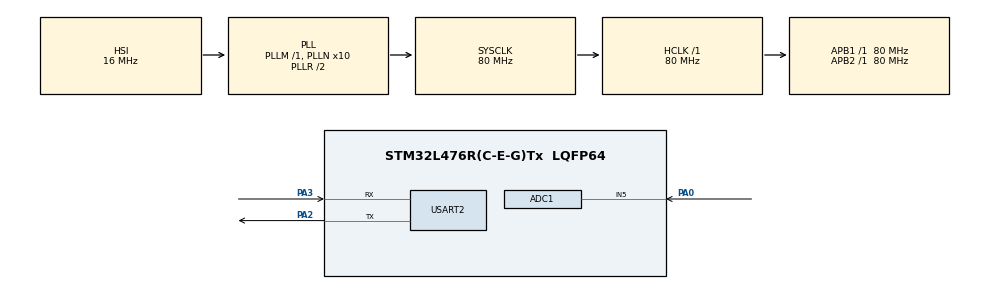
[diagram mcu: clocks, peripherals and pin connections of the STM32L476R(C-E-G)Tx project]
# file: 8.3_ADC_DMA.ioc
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ADC1.Channel-0\#ChannelRegularConversion=ADC_CHANNEL_5
ADC1.ClockPrescaler=ADC_CLOCK_ASYNC_DIV1
ADC1.ContinuousConvMode=ENABLE
ADC1.DMAContinuousRequests=ENABLE
ADC1.NbrOfConversionFlag=1
ADC1.OffsetNumber-0\#ChannelRegularConversion=ADC_OFFSET_NONE
ADC1.Rank-0\#ChannelRegularConversion=1
ADC1.SamplingTime-0\#ChannelRegularConversion=ADC_SAMPLETIME_2CYCLES_5
ADC1.master=1
Dma.ADC1.0.Direction=DMA_PERIPH_TO_MEMORY
Dma.ADC1.0.Instance=DMA1_Channel1
Dma.ADC1.0.MemDataAlignment=DMA_MDATAALIGN_HALFWORD
Dma.ADC1.0.MemInc=DMA_MINC_ENABLE
Dma.ADC1.0.Mode=DMA_CIRCULAR
Dma.ADC1.0.PeriphDataAlignment=DMA_PDATAALIGN_HALFWORD
Dma.ADC1.0.PeriphInc=DMA_PINC_DISABLE
Dma.ADC1.0.Priority=DMA_PRIORITY_LOW
Dma.Request0=ADC1
Mcu.Family=STM32L4
Mcu.Name=STM32L476R(C-E-G)Tx
Mcu.Package=LQFP64
NVIC.DMA1_Channel1_IRQn=true\:0\:0\:false\:false\:true\:false\:true\:true
NVIC.PriorityGroup=NVIC_PRIORITYGROUP_4
PA0.Signal=ADCx_IN5
PA13\ (JTMS-SWDIO).Mode=Serial_Wire
PA13\ (JTMS-SWDIO).Signal=SYS_JTMS-SWDIO
PA14\ (JTCK-SWCLK).Mode=Serial_Wire
PA14\ (JTCK-SWCLK).Signal=SYS_JTCK-SWCLK
PA2.Mode=Asynchronous
PA2.Signal=USART2_TX
PA3.Mode=Asynchronous
PA3.Signal=USART2_RX
ProjectManager.HeapSize=0x200
ProjectManager.StackSize=0x400
ProjectManager.TargetToolchain=STM32CubeIDE
RCC.ADCFreq_Value=64000000
RCC.AHBFreq_Value=80000000
RCC.APB1Freq_Value=80000000
RCC.APB1TimFreq_Value=80000000
RCC.APB2Freq_Value=80000000
RCC.APB2TimFreq_Value=80000000
RCC.CortexFreq_Value=80000000
RCC.HCLKFreq_Value=80000000
RCC.HSE_VALUE=8000000
RCC.HSI_VALUE=16000000
RCC.LSE_VALUE=32768
RCC.MSI_VALUE=4000000
RCC.PLLN=10
RCC.PLLSourceVirtual=RCC_PLLSOURCE_HSI
RCC.SYSCLKFreq_VALUE=80000000
RCC.SYSCLKSource=RCC_SYSCLKSOURCE_PLLCLK
RCC.USBFreq_Value=64000000
RCC.VCOOutputFreq_Value=160000000
SH.ADCx_IN5.0=ADC1_IN5,IN5-Single-Ended
USART2.VirtualMode-Asynchronous=VM_ASYNC
board=custom

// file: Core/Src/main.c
/* USER CODE BEGIN Header */
/**
  ******************************************************************************
  * @file           : main.c
  * @brief          : Main program body
  ******************************************************************************
  * @attention
  *
  * Copyright (c) 2024 STMicroelectronics.
  * All rights reserved.
  *
  * This software is licensed under terms that can be found in the LICENSE file
  * in the root directory of this software component.
  * If no LICENSE file comes with this software, it is provided AS-IS.
  *
  ******************************************************************************
  */
/* USER CODE END Header */
#include "main.h"

/* USER CODE BEGIN Includes */
#include <stdio.h>
/* USER CODE END Includes */

ADC_HandleTypeDef hadc1;
DMA_HandleTypeDef hdma_adc1;

UART_HandleTypeDef huart2;

/* USER CODE BEGIN PV */
//uint32_t  port_value;
//uint32_t ra;
uint16_t adc_buf[4096];
/* USER CODE END PV */

void SystemClock_Config(void);
static void MX_GPIO_Init(void);
static void MX_DMA_Init(void);
static void MX_ADC1_Init(void);
static void MX_USART2_UART_Init(void);

int main(void)
{

  /* MCU Configuration--------------------------------------------------------*/

  /* Reset of all peripherals, Initializes the Flash interface and the Systick. */
  HAL_Init();

  /* Configure the system clock */
  SystemClock_Config();

  /* Initialize all configured peripherals */
  MX_GPIO_Init();
  MX_DMA_Init();
  MX_ADC1_Init();
  MX_USART2_UART_Init();
  /* USER CODE BEGIN 2 */
  HAL_ADC_Start_DMA(&hadc1, (uint32_t *)adc_buf, sizeof(adc_buf));
  /* USER CODE END 2 */

  /* Infinite loop */
  while (1)
  {

  }
}

void SystemClock_Config(void)
{
  RCC_OscInitTypeDef RCC_OscInitStruct = {0};
  RCC_ClkInitTypeDef RCC_ClkInitStruct = {0};

  /** Configure the main internal regulator output voltage
  */
  if (HAL_PWREx_ControlVoltageScaling(PWR_REGULATOR_VOLTAGE_SCALE1) != HAL_OK)
  {
    Error_Handler();
  }

  /** Initializes the RCC Oscillators according to the specified parameters
  * in the RCC_OscInitTypeDef structure.
  */
  RCC_OscInitStruct.OscillatorType = RCC_OSCILLATORTYPE_HSI;
  RCC_OscInitStruct.HSIState = RCC_HSI_ON;
  RCC_OscInitStruct.HSICalibrationValue = RCC_HSICALIBRATION_DEFAULT;
  RCC_OscInitStruct.PLL.PLLState = RCC_PLL_ON;
  RCC_OscInitStruct.PLL.PLLSource = RCC_PLLSOURCE_HSI;
  RCC_OscInitStruct.PLL.PLLM = 1;
  RCC_OscInitStruct.PLL.PLLN = 10;
  RCC_OscInitStruct.PLL.PLLP = RCC_PLLP_DIV7;
  RCC_OscInitStruct.PLL.PLLQ = RCC_PLLQ_DIV2;
  RCC_OscInitStruct.PLL.PLLR = RCC_PLLR_DIV2;
  if (HAL_RCC_OscConfig(&RCC_OscInitStruct) != HAL_OK)
  {
    Error_Handler();
  }

  /** Initializes the CPU, AHB and APB buses clocks
  */
  RCC_ClkInitStruct.ClockType = RCC_CLOCKTYPE_HCLK|RCC_CLOCKTYPE_SYSCLK
                              |RCC_CLOCKTYPE_PCLK1|RCC_CLOCKTYPE_PCLK2;
  RCC_ClkInitStruct.SYSCLKSource = RCC_SYSCLKSOURCE_PLLCLK;
  RCC_ClkInitStruct.AHBCLKDivider = RCC_SYSCLK_DIV1;
  RCC_ClkInitStruct.APB1CLKDivider = RCC_HCLK_DIV1;
  RCC_ClkInitStruct.APB2CLKDivider = RCC_HCLK_DIV1;

  if (HAL_RCC_ClockConfig(&RCC_ClkInitStruct, FLASH_LATENCY_4) != HAL_OK)
  {
    Error_Handler();
  }
}

static void MX_ADC1_Init(void)
{

  ADC_MultiModeTypeDef multimode = {0};
  ADC_ChannelConfTypeDef sConfig = {0};

  /** Common config
  */
  hadc1.Instance = ADC1;
  hadc1.Init.ClockPrescaler = ADC_CLOCK_ASYNC_DIV1;
  hadc1.Init.Resolution = ADC_RESOLUTION_12B;
  hadc1.Init.DataAlign = ADC_DATAALIGN_RIGHT;
  hadc1.Init.ScanConvMode = ADC_SCAN_DISABLE;
  hadc1.Init.EOCSelection = ADC_EOC_SINGLE_CONV;
  hadc1.Init.LowPowerAutoWait = DISABLE;
  hadc1.Init.ContinuousConvMode = ENABLE;
  hadc1.Init.NbrOfConversion = 1;
  hadc1.Init.DiscontinuousConvMode = DISABLE;
  hadc1.Init.ExternalTrigConv = ADC_SOFTWARE_START;
  hadc1.Init.ExternalTrigConvEdge = ADC_EXTERNALTRIGCONVEDGE_NONE;
  hadc1.Init.DMAContinuousRequests = ENABLE;
  hadc1.Init.Overrun = ADC_OVR_DATA_PRESERVED;
  hadc1.Init.OversamplingMode = DISABLE;
  if (HAL_ADC_Init(&hadc1) != HAL_OK)
  {
    Error_Handler();
  }

  /** Configure the ADC multi-mode
  */
  multimode.Mode = ADC_MODE_INDEPENDENT;
  if (HAL_ADCEx_MultiModeConfigChannel(&hadc1, &multimode) != HAL_OK)
  {
    Error_Handler();
  }

  /** Configure Regular Channel
  */
  sConfig.Channel = ADC_CHANNEL_5;
  sConfig.Rank = ADC_REGULAR_RANK_1;
  sConfig.SamplingTime = ADC_SAMPLETIME_2CYCLES_5;
  sConfig.SingleDiff = ADC_SINGLE_ENDED;
  sConfig.OffsetNumber = ADC_OFFSET_NONE;
  sConfig.Offset = 0;
  if (HAL_ADC_ConfigChannel(&hadc1, &sConfig) != HAL_OK)
  {
    Error_Handler();
  }

}

static void MX_USART2_UART_Init(void)
{

  huart2.Instance = USART2;
  huart2.Init.BaudRate = 115200;
  huart2.Init.WordLength = UART_WORDLENGTH_8B;
  huart2.Init.StopBits = UART_STOPBITS_1;
  huart2.Init.Parity = UART_PARITY_NONE;
  huart2.Init.Mode = UART_MODE_TX_RX;
  huart2.Init.HwFlowCtl = UART_HWCONTROL_NONE;
  huart2.Init.OverSampling = UART_OVERSAMPLING_16;
  huart2.Init.OneBitSampling = UART_ONE_BIT_SAMPLE_DISABLE;
  huart2.AdvancedInit.AdvFeatureInit = UART_ADVFEATURE_NO_INIT;
  if (HAL_UART_Init(&huart2) != HAL_OK)
  {
    Error_Handler();
  }

}

static void MX_DMA_Init(void)
{

  /* DMA controller clock enable */
  __HAL_RCC_DMA1_CLK_ENABLE();

  /* DMA interrupt init */
  /* DMA1_Channel1_IRQn interrupt configuration */
  HAL_NVIC_SetPriority(DMA1_Channel1_IRQn, 0, 0);
  HAL_NVIC_EnableIRQ(DMA1_Channel1_IRQn);

}

static void MX_GPIO_Init(void)
{

  /* GPIO Ports Clock Enable */
  __HAL_RCC_GPIOA_CLK_ENABLE();

}

/* USER CODE BEGIN 4 */
//void HAL_ADC_ConvCpltCallback(ADC_HandleTypeDef* hadc){
//	port_value=ra;
//	printf("%d \r\n",(int)port_value);
//
//	  HAL_ADC_Start_DMA(&hadc1, &ra, sizeof(ra));
//
//}
void HAL_ADC_ConvHalfCpltCallback(ADC_HandleTypeDef* hadc){
	printf("HALF DATA IS STORED\r\n");
}

void HAL_ADC_ConvCpltCallback(ADC_HandleTypeDef* hadc){
	printf("ALL DATA IS STORED\r\n");
}
/* USER CODE END 4 */

void Error_Handler(void)
{
  __disable_irq();
  while (1)
  {
  }
}
